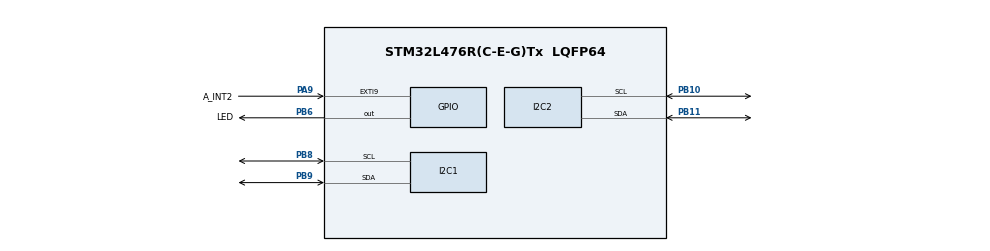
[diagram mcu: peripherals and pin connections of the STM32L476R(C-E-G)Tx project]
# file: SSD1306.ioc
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Mcu.Family=STM32L4
Mcu.Name=STM32L476R(C-E-G)Tx
Mcu.Package=LQFP64
NVIC.EXTI9_5_IRQn=true\:0\:0\:false\:false\:true\:true\:true\:true
NVIC.PriorityGroup=NVIC_PRIORITYGROUP_4
PA13\ (JTMS-SWDIO).Mode=Trace_Asynchronous_SW
PA13\ (JTMS-SWDIO).Signal=SYS_JTMS-SWDIO
PA14\ (JTCK-SWCLK).Mode=Trace_Asynchronous_SW
PA14\ (JTCK-SWCLK).Signal=SYS_JTCK-SWCLK
PA9.GPIO_Label=A_INT2
PA9.Signal=GPXTI9
PB10.GPIO_Pu=GPIO_PULLUP
PB10.Mode=I2C
PB10.Signal=I2C2_SCL
PB11.GPIO_Pu=GPIO_PULLUP
PB11.Mode=I2C
PB11.Signal=I2C2_SDA
PB3\ (JTDO-TRACESWO).Mode=Trace_Asynchronous_SW
PB3\ (JTDO-TRACESWO).Signal=SYS_JTDO-SWO
PB6.GPIO_Label=LED
PB6.Signal=GPIO_Output
PB8.GPIO_Pu=GPIO_PULLUP
PB8.Mode=I2C
PB8.Signal=I2C1_SCL
PB9.GPIO_Pu=GPIO_PULLUP
PB9.Mode=I2C
PB9.Signal=I2C1_SDA
PH0-OSC_IN\ (PH0).Mode=HSE-External-Oscillator
PH0-OSC_IN\ (PH0).Signal=RCC_OSC_IN
PH1-OSC_OUT\ (PH1).Mode=HSE-External-Oscillator
PH1-OSC_OUT\ (PH1).Signal=RCC_OSC_OUT
ProjectManager.HeapSize=0x200
ProjectManager.StackSize=0x400
ProjectManager.TargetToolchain=STM32CubeIDE
RCC.ADCFreq_Value=64000000
RCC.HSE_VALUE=8000000
RCC.HSI_VALUE=16000000
RCC.LSE_VALUE=32768
RCC.MSI_VALUE=4000000
RCC.PLLSourceVirtual=RCC_PLLSOURCE_HSI
RCC.USBFreq_Value=64000000
RCC.VCOOutputFreq_Value=128000000
board=custom

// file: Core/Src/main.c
/* USER CODE BEGIN Header */
/**
  ******************************************************************************
  * @file           : main.c
  * @brief          : Main program body for SSD1306 driver
  ******************************************************************************
  * @attention
  *
  * Copyright (c) 2022 STMicroelectronics.
  * All rights reserved.
  *
  * This software is licensed under terms that can be found in the LICENSE file
  * in the root directory of this software component.
  * If no LICENSE file comes with this software, it is provided AS-IS.
  *
  ******************************************************************************
  */
/* USER CODE END Header */
#include "main.h"
//#include "oled.h"

/* USER CODE BEGIN Includes */
#include "SSD1306.h"

/* USER CODE END Includes */

I2C_HandleTypeDef hi2c1;
I2C_HandleTypeDef hi2c2;

/* USER CODE BEGIN PV */
SSD1306_t disp;

/* USER CODE END PV */

void SystemClock_Config(void);
static void MX_GPIO_Init(void);
static void MX_I2C1_Init(void);
static void MX_I2C2_Init(void);

int main(void)
{

  /* MCU Configuration--------------------------------------------------------*/

  /* Reset of all peripherals, Initializes the Flash interface and the Systick. */
  HAL_Init();

  /* Configure the system clock */
  SystemClock_Config();

  /* Initialize all configured peripherals */
  MX_GPIO_Init();
  MX_I2C1_Init();
  MX_I2C2_Init();
  /* USER CODE BEGIN 2 */

  // Initialise display
  SSD1306_Initialise(&disp, &hi2c2);

  /* USER CODE END 2 */

  /* Infinite loop */
  while (1)
  {
	 // ADXL345_ReadAccelerations(&acc); executable code

	  //SSD1306_Puts ("Embedded", &Font_7x10, 1);

	  SSD1306_ScreenUpdate(&disp);
  }
}

void SystemClock_Config(void)
{
  RCC_OscInitTypeDef RCC_OscInitStruct = {0};
  RCC_ClkInitTypeDef RCC_ClkInitStruct = {0};

  /** Configure the main internal regulator output voltage
  */
  if (HAL_PWREx_ControlVoltageScaling(PWR_REGULATOR_VOLTAGE_SCALE1) != HAL_OK)
  {
    Error_Handler();
  }

  /** Initializes the RCC Oscillators according to the specified parameters
  * in the RCC_OscInitTypeDef structure.
  */
  RCC_OscInitStruct.OscillatorType = RCC_OSCILLATORTYPE_MSI;
  RCC_OscInitStruct.MSIState = RCC_MSI_ON;
  RCC_OscInitStruct.MSICalibrationValue = 0;
  RCC_OscInitStruct.MSIClockRange = RCC_MSIRANGE_6;
  RCC_OscInitStruct.PLL.PLLState = RCC_PLL_NONE;
  if (HAL_RCC_OscConfig(&RCC_OscInitStruct) != HAL_OK)
  {
    Error_Handler();
  }

  /** Initializes the CPU, AHB and APB buses clocks
  */
  RCC_ClkInitStruct.ClockType = RCC_CLOCKTYPE_HCLK|RCC_CLOCKTYPE_SYSCLK
                              |RCC_CLOCKTYPE_PCLK1|RCC_CLOCKTYPE_PCLK2;
  RCC_ClkInitStruct.SYSCLKSource = RCC_SYSCLKSOURCE_MSI;
  RCC_ClkInitStruct.AHBCLKDivider = RCC_SYSCLK_DIV1;
  RCC_ClkInitStruct.APB1CLKDivider = RCC_HCLK_DIV1;
  RCC_ClkInitStruct.APB2CLKDivider = RCC_HCLK_DIV1;

  if (HAL_RCC_ClockConfig(&RCC_ClkInitStruct, FLASH_LATENCY_0) != HAL_OK)
  {
    Error_Handler();
  }
}

static void MX_I2C1_Init(void)
{

  hi2c1.Instance = I2C1;
  hi2c1.Init.Timing = 0x00000E14;
  hi2c1.Init.OwnAddress1 = 0;
  hi2c1.Init.AddressingMode = I2C_ADDRESSINGMODE_7BIT;
  hi2c1.Init.DualAddressMode = I2C_DUALADDRESS_DISABLE;
  hi2c1.Init.OwnAddress2 = 0;
  hi2c1.Init.OwnAddress2Masks = I2C_OA2_NOMASK;
  hi2c1.Init.GeneralCallMode = I2C_GENERALCALL_DISABLE;
  hi2c1.Init.NoStretchMode = I2C_NOSTRETCH_DISABLE;
  if (HAL_I2C_Init(&hi2c1) != HAL_OK)
  {
    Error_Handler();
  }

  /** Configure Analogue filter
  */
  if (HAL_I2CEx_ConfigAnalogFilter(&hi2c1, I2C_ANALOGFILTER_ENABLE) != HAL_OK)
  {
    Error_Handler();
  }

  /** Configure Digital filter
  */
  if (HAL_I2CEx_ConfigDigitalFilter(&hi2c1, 0) != HAL_OK)
  {
    Error_Handler();
  }

}

static void MX_I2C2_Init(void)
{

  hi2c2.Instance = I2C2;
  hi2c2.Init.Timing = 0x00000E14;
  hi2c2.Init.OwnAddress1 = 0;
  hi2c2.Init.AddressingMode = I2C_ADDRESSINGMODE_7BIT;
  hi2c2.Init.DualAddressMode = I2C_DUALADDRESS_DISABLE;
  hi2c2.Init.OwnAddress2 = 0;
  hi2c2.Init.OwnAddress2Masks = I2C_OA2_NOMASK;
  hi2c2.Init.GeneralCallMode = I2C_GENERALCALL_DISABLE;
  hi2c2.Init.NoStretchMode = I2C_NOSTRETCH_DISABLE;
  if (HAL_I2C_Init(&hi2c2) != HAL_OK)
  {
    Error_Handler();
  }

  /** Configure Analogue filter
  */
  if (HAL_I2CEx_ConfigAnalogFilter(&hi2c2, I2C_ANALOGFILTER_ENABLE) != HAL_OK)
  {
    Error_Handler();
  }

  /** Configure Digital filter
  */
  if (HAL_I2CEx_ConfigDigitalFilter(&hi2c2, 0) != HAL_OK)
  {
    Error_Handler();
  }

}

static void MX_GPIO_Init(void)
{
  GPIO_InitTypeDef GPIO_InitStruct = {0};

  /* GPIO Ports Clock Enable */
  __HAL_RCC_GPIOH_CLK_ENABLE();
  __HAL_RCC_GPIOB_CLK_ENABLE();
  __HAL_RCC_GPIOA_CLK_ENABLE();

  /*Configure GPIO pin Output Level */
  HAL_GPIO_WritePin(LED_GPIO_Port, LED_Pin, GPIO_PIN_RESET);

  /*Configure GPIO pin : A_INT2_Pin */
  GPIO_InitStruct.Pin = A_INT2_Pin;
  GPIO_InitStruct.Mode = GPIO_MODE_IT_RISING;
  GPIO_InitStruct.Pull = GPIO_NOPULL;
  HAL_GPIO_Init(A_INT2_GPIO_Port, &GPIO_InitStruct);

  /*Configure GPIO pin : LED_Pin */
  GPIO_InitStruct.Pin = LED_Pin;
  GPIO_InitStruct.Mode = GPIO_MODE_OUTPUT_PP;
  GPIO_InitStruct.Pull = GPIO_NOPULL;
  GPIO_InitStruct.Speed = GPIO_SPEED_FREQ_LOW;
  HAL_GPIO_Init(LED_GPIO_Port, &GPIO_InitStruct);

  /* EXTI interrupt init*/
  HAL_NVIC_SetPriority(EXTI9_5_IRQn, 0, 0);
  HAL_NVIC_EnableIRQ(EXTI9_5_IRQn);

}

void Error_Handler(void)
{
  __disable_irq();
  while (1)
  {
  }
}
